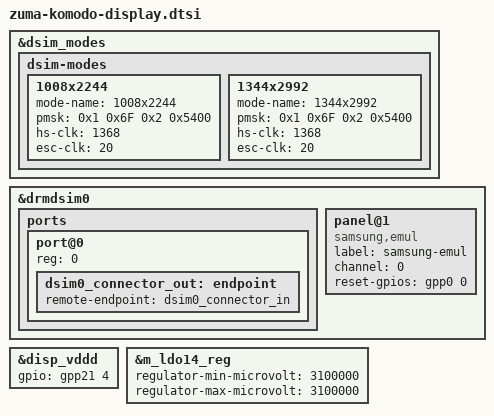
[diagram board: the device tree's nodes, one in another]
// SPDX-License-Identifier: GPL-2.0-only
/*
 * Display nodes for komodo-related boards.
 *
 * Copyright 2023 Google LLC
 *
 */

#include <dt-bindings/gpio/gpio.h>
#include "zuma-komodo-connector.dtsi"

&dsim_modes {
	dsim-modes {
		1008x2244 {
			mode-name = "1008x2244";
			pmsk = <
				0x1 0x6F 0x2 0x5400 /* p m s k */
				>;
			hs-clk = <1368>;
			esc-clk = <20>;
		};
		1344x2992 {
			mode-name = "1344x2992";
			pmsk = <
				0x1 0x6F 0x2 0x5400 /* p m s k */
				>;
			hs-clk = <1368>;
			esc-clk = <20>;
		};
	};
};

&drmdsim0 {
	#address-cells = <1>;
	#size-cells = <0>;

	ports {
		#address-cells = <1>;
		#size-cells = <0>;
		port@0 {
			reg = <0>;
			/* output */
			dsim0_connector_out: endpoint {
				remote-endpoint = <&dsim0_connector_in>;
			};
		};
	};
	panel@1 {
		compatible = "samsung,emul";
		label = "samsung-emul";
		channel = <0>;

		/* reset, power */
		reset-gpios = <&gpp0 0 GPIO_ACTIVE_HIGH>;
	};
};

&disp_vddd {
	status = "okay";
	gpio = <&gpp21 4 GPIO_ACTIVE_HIGH>;
};

&m_ldo14_reg {
	regulator-min-microvolt = <3100000>;
	regulator-max-microvolt = <3100000>;
	/delete-property/ regulator-always-on;
};
